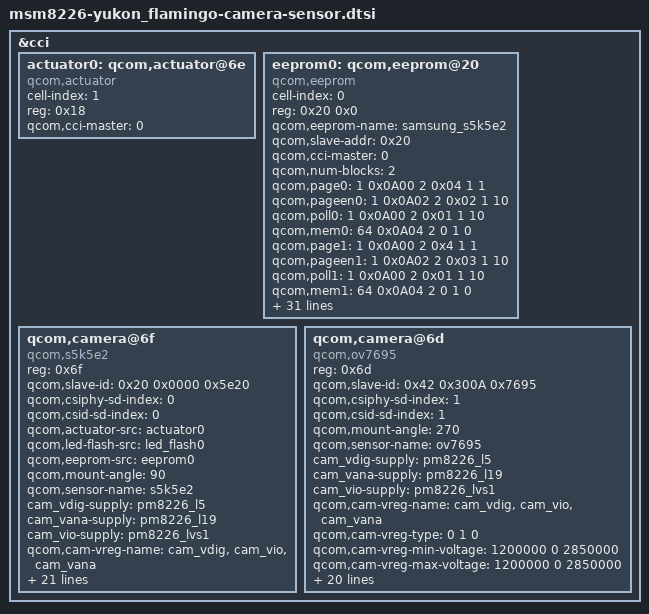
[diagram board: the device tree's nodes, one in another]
/*
 * Copyright (c) 2013, The Linux Foundation. All rights reserved.
 *
 * This program is free software; you can redistribute it and/or modify
 * it under the terms of the GNU General Public License version 2 and
 * only version 2 as published by the Free Software Foundation.
 *
 * This program is distributed in the hope that it will be useful,
 * but WITHOUT ANY WARRANTY; without even the implied warranty of
 * MERCHANTABILITY or FITNESS FOR A PARTICULAR PURPOSE.  See the
 * GNU General Public License for more details.
 */
 
&cci {
	actuator0: qcom,actuator@6e {
		cell-index = <1>;
		reg = <0x18>;
		compatible = "qcom,actuator";
		qcom,cci-master = <0>;
	};

	eeprom0: qcom,eeprom@20 {
		cell-index = <0>;
		reg = <0x20 0x0>;
		qcom,eeprom-name = "samsung_s5k5e2";
		compatible = "qcom,eeprom";
		qcom,slave-addr = <0x20>;
		qcom,cci-master = <0>;
		qcom,num-blocks = <2>;

		qcom,page0 = <1 0x0A00 2 0x04 1 1>;
		qcom,pageen0 = <1 0x0A02 2 0x02 1 10>;
		qcom,poll0 = <1 0x0A00 2 0x01 1 10>;
		qcom,mem0 = <64 0x0A04 2 0 1 0>;
		
		qcom,page1 = <1 0x0A00 2 0x4 1 1>;
		qcom,pageen1 = <1 0x0A02 2 0x03 1 10>;
		qcom,poll1 = <1 0x0A00 2 0x01 1 10>;
		qcom,mem1 = <64 0x0A04 2 0 1 0>;
		
		cam_vdig-supply = <&pm8226_l5>;
		cam_vio-supply = <&pm8226_lvs1>;
		qcom,cam-vreg-name = "cam_vdig", "cam_vio";
		qcom,cam-vreg-type = <0 1>;
		qcom,cam-vreg-min-voltage = <1200000 0>;
		qcom,cam-vreg-max-voltage = <1200000 0>;
		qcom,cam-vreg-op-mode = <200000 0>;
		qcom,gpio-no-mux = <0>;
		
		gpios = <&msmgpio 26 0>,
			<&msmgpio 37 0>,
			<&msmgpio 12 0>,
			<&msmgpio 13 0>,
			<&msmgpio 120 0>;
		qcom,gpio-reset = <1>;
		qcom,gpio-vio = <2>;
		qcom,gpio-vana = <3>;
		qcom,gpio-vaf = <4>;
		qcom,gpio-req-tbl-num = <0 1 2 3 4>;
		qcom,gpio-req-tbl-flags = <1 0 0 0 0>;
		qcom,gpio-req-tbl-label = "CAMIF_MCLK",
			"CAM_RESET1",
			"CAM1_1V8_EN",
			"CAM1_2V8_EN",
			"CAM1_2V7_EN";
			
		qcom,cam-power-seq-type = "sensor_vreg",
			"sensor_gpio", "sensor_gpio",
			"sensor_gpio", "sensor_gpio", 
			"sensor_vreg","sensor_gpio",
			"sensor_gpio","sensor_clk","sensor_i2c_mux";
		qcom,cam-power-seq-val = "cam_vio",
			"sensor_gpio_vio","sensor_gpio_vio",
			"sensor_gpio_vana","sensor_gpio_vana",
			"cam_vdig","sensor_gpio_reset",
			"sensor_gpio_reset","sensor_cam_mclk","none";
		qcom,cam-power-seq-cfg-val = <0 0 1 0 1 0 0 1 24000000 0>;
		qcom,cam-power-seq-delay = <0 0 0 0 0 0 0 5 5 0>;

	};
	
	qcom,camera@6f {
		compatible = "qcom,s5k5e2";
		reg = <0x6f>;
		qcom,slave-id = <0x20 0x0000 0x5e20>;
		qcom,csiphy-sd-index = <0>;
		qcom,csid-sd-index = <0>;
		qcom,actuator-src = <&actuator0>;
		qcom,led-flash-src = <&led_flash0>;
		qcom,eeprom-src = <&eeprom0>;
		qcom,mount-angle = <90>;
		qcom,sensor-name = "s5k5e2";
		cam_vdig-supply = <&pm8226_l5>;
		cam_vana-supply = <&pm8226_l19>;
		cam_vio-supply = <&pm8226_lvs1>;
		qcom,cam-vreg-name = "cam_vdig", "cam_vio", "cam_vana";
		qcom,cam-vreg-type = <0 1 0>;
		qcom,cam-vreg-min-voltage = <1200000 0 2850000>;
		qcom,cam-vreg-max-voltage = <1200000 0 2850000>;
		qcom,cam-vreg-op-mode = <200000 0 80000>;
		qcom,gpio-no-mux = <0>;
		gpios = <&msmgpio 26 0>,
			<&msmgpio 37 0>,
			<&msmgpio 12 0>,
			<&msmgpio 13 0>,
			<&msmgpio 120 0>;
		qcom,gpio-reset = <1>;
		qcom,gpio-vio = <2>;
		qcom,gpio-vana = <3>;
		qcom,gpio-vaf = <4>;
                qcom,gpio-req-tbl-num = <0 1 2 3 4>;
		qcom,gpio-req-tbl-flags = <1 0 0 0 0>;
		qcom,gpio-req-tbl-label = "CAMIF_MCLK",
			"CAM_RESET1",
			"CAM1_1V8_EN",
			"CAM1_2V8_EN",
			"CAM1_2V7_EN";
		qcom,csi-lane-assign = <0x4320>;
		qcom,csi-lane-mask = <0x1f>;
		qcom,sensor-position = <0>;
		qcom,sensor-mode = <0>;
		qcom,cci-master = <0>;
	};

	qcom,camera@6d {
		compatible = "qcom,ov7695";
		reg = <0x6d>;
		qcom,slave-id = <0x42 0x300A 0x7695>;
		qcom,csiphy-sd-index = <1>;
		qcom,csid-sd-index = <1>;
		qcom,mount-angle = <270>;
		qcom,sensor-name = "ov7695";
		cam_vdig-supply = <&pm8226_l5>;
		cam_vana-supply = <&pm8226_l19>;
		cam_vio-supply = <&pm8226_lvs1>;
		qcom,cam-vreg-name = "cam_vdig", "cam_vio", "cam_vana";
		qcom,cam-vreg-type = <0 1 0>;
		qcom,cam-vreg-min-voltage = <1200000 0 2850000>;
		qcom,cam-vreg-max-voltage = <1200000 0 2850000>;
		qcom,cam-vreg-op-mode = <200000 0 80000>;
		qcom,gpio-no-mux = <0>;
		gpios = <&msmgpio 26 0>,
				<&msmgpio 28 0>,
				<&msmgpio 12 0>,
				<&msmgpio 13 0>;
		qcom,gpio-reset = <1>;
		qcom,gpio-vio = <2>;
		qcom,gpio-vana = <3>;
		qcom,gpio-req-tbl-num = <0 1 2 3 >;
		qcom,gpio-req-tbl-flags = <1 0 0 0 >;
		qcom,gpio-req-tbl-label = "CAMIF_MCLK",
				"CAM_RESET",
				"CAM_VDIG_EN",
				"CAM_VANA_EN",
				"CAM_VIO_EN";
		qcom,gpio-set-tbl-num = <1 1>;
		qcom,gpio-set-tbl-flags = <0 2>;
		qcom,gpio-set-tbl-delay = <1000 4000>;
		qcom,csi-lane-assign = <0x4320>;
		qcom,csi-lane-mask = <0x3>;
		qcom,sensor-position = <1>;
		qcom,sensor-mode = <1>;
		qcom,cci-master = <0>;
		status = "ok";
	};
};
